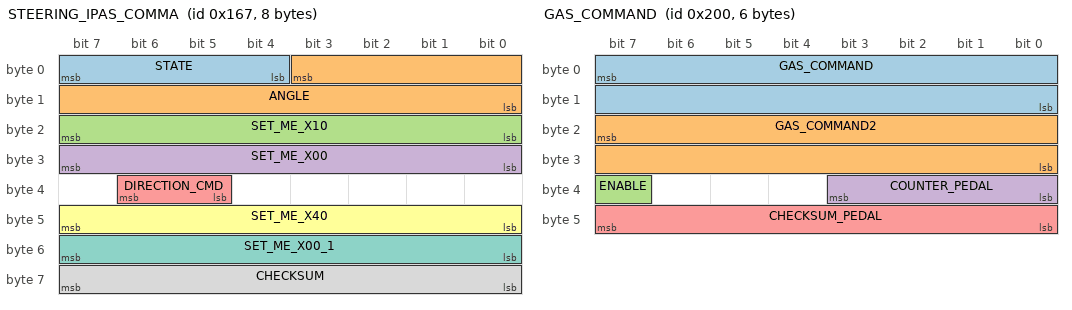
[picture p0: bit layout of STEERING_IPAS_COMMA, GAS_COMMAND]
BO_ 359 STEERING_IPAS_COMMA: 8 IPAS
 SG_ STATE : 7|4@0+ (1,0) [0|15] "" XXX
 SG_ ANGLE : 3|12@0- (1.5,0) [-510|510] "deg" XXX
 SG_ SET_ME_X10 : 23|8@0+ (1,0) [0|255] "" XXX
 SG_ SET_ME_X00 : 31|8@0+ (1,0) [0|255] "" XXX
 SG_ DIRECTION_CMD : 38|2@0+ (1,0) [0|3] "" XXX
 SG_ SET_ME_X40 : 47|8@0+ (1,0) [0|255] "" XXX
 SG_ SET_ME_X00_1 : 55|8@0+ (1,0) [0|255] "" XXX
 SG_ CHECKSUM : 63|8@0+ (1,0) [0|255] "" XXX

CM_ "BO_ STEERING_IPAS_COMMA: Copy of msg 614 so we can do angle control while the Park Assist ECU is connected (Panda spoofs 614 with 359 on connector J70). Note that addresses 0x266 and 0x167 are checksum-invariant";

BO_ 512 GAS_COMMAND: 6 EON
 SG_ GAS_COMMAND : 7|16@0+ (0.159375,-75.555) [0|1] "" INTERCEPTOR
 SG_ GAS_COMMAND2 : 23|16@0+ (0.159375,-151.111) [0|1] "" INTERCEPTOR
 SG_ ENABLE : 39|1@0+ (1,0) [0|1] "" INTERCEPTOR
 SG_ COUNTER_PEDAL : 35|4@0+ (1,0) [0|15] "" INTERCEPTOR
 SG_ CHECKSUM_PEDAL : 47|8@0+ (1,0) [0|255] "" INTERCEPTOR

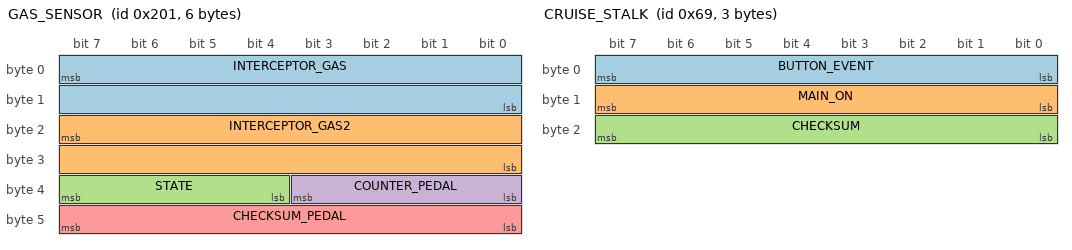
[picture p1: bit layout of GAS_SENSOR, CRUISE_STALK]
BO_ 513 GAS_SENSOR: 6 INTERCEPTOR
 SG_ INTERCEPTOR_GAS : 7|16@0+ (1,0) [0|1] "" EON
 SG_ INTERCEPTOR_GAS2 : 23|16@0+ (1,0) [0|1] "" EON
 SG_ STATE : 39|4@0+ (1,0) [0|15] "" EON
 SG_ COUNTER_PEDAL : 35|4@0+ (1,0) [0|15] "" EON
 SG_ CHECKSUM_PEDAL : 47|8@0+ (1,0) [0|255] "" EON

VAL_ 513 STATE 5 "FAULT_TIMEOUT" 4 "FAULT_STARTUP" 3 "FAULT_SCE" 2 "FAULT_SEND" 1 "FAULT_BAD_CHECKSUM" 0 "NO_FAULT" ;

BO_ 35 SECONDARY_STEER_ANGLE: 8 XXX
 SG_ ZORRO_STEER : 7|24@0- (0.004901594652,0) [-500|500] "" XXX

CM_ "BO_ SECONDARY_STEER_ANGLE: ZSS is a high-precision steering angle sensor that can replace the lower resolution sensor in most TSS1 Toyotas. Learn more: https://github.com/commaai/openpilot/wiki/Toyota-Lexus#zorro-steering-sensor-zss";

BO_ 767 SDSU: 8 XXX
 SG_ FD_BUTTON : 7|1@0+ (1,0) [0|1] "" XXX
 SG_ STATE : 23|4@0+ (1,0) [0|15] "" XXX

CM_ "BO_ SDSU: The sDSU is a modified DSU for use in TSS-P Toyotas. Learn more: https://github.com/RetroPilot/ocelot/tree/main/firmware/smart_dsu";
CM_ SG_ 767 FD_BUTTON "The follow distance button signal as forwarded by the sdsu";

VAL_ 767 STATE 7 "STATE_AEB_CTRL" 6 "FAULT_INVALID" 5 "FAULT_TIMEOUT" 4 "FAULT_STARTUP" 3 "FAULT_SCE" 2 "FAULT_SEND" 1 "FAULT_BAD_CHECKSUM" 0 "NO_FAULT" ;

BO_ 105 CRUISE_STALK: 3 RETROFIT
 SG_ BUTTON_EVENT : 7|8@0+ (1,0) [0|4] "" XXX
 SG_ MAIN_ON : 15|8@0+ (1,0) [0|1] "" XXX
 SG_ CHECKSUM : 23|8@0+ (1,0) [0|255] "" XXX

CM_ "BO_ CRUISE_STALK: Retrofit (TOYOTA_COROLLA_RETROFIT) cruise stalk ECU, 20 Hz. BUTTON_EVENT is set for one frame per press; MAIN_ON is sent every frame. Source: corolla_emulator/cruise_stalk.";
VAL_ 105 BUTTON_EVENT 4 "MAIN_TOGGLE" 3 "CANCEL" 2 "RES" 1 "SET" 0 "NONE" ;

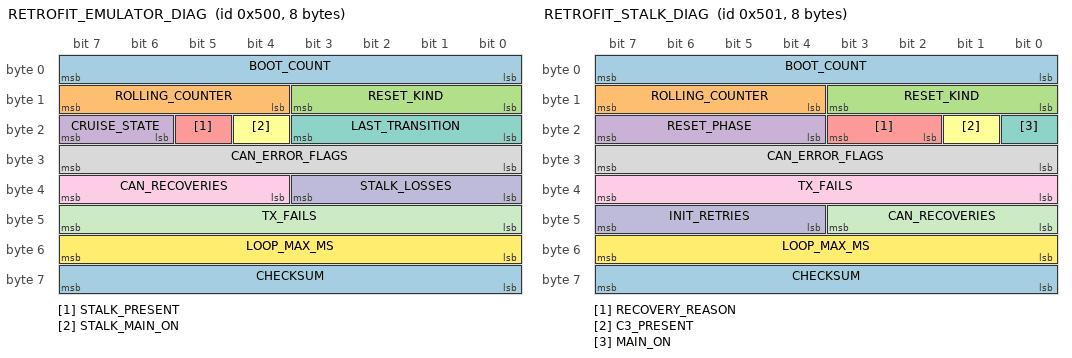
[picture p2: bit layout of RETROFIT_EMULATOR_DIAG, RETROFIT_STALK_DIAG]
BO_ 1280 RETROFIT_EMULATOR_DIAG: 8 RETROFIT
 SG_ BOOT_COUNT : 7|8@0+ (1,0) [0|255] "" XXX
 SG_ ROLLING_COUNTER : 15|4@0+ (1,0) [0|15] "" XXX
 SG_ RESET_KIND : 11|4@0+ (1,0) [0|15] "" XXX
 SG_ CRUISE_STATE : 23|2@0+ (1,0) [0|3] "" XXX
 SG_ STALK_PRESENT : 21|1@0+ (1,0) [0|1] "" XXX
 SG_ STALK_MAIN_ON : 20|1@0+ (1,0) [0|1] "" XXX
 SG_ LAST_TRANSITION : 19|4@0+ (1,0) [0|15] "" XXX
 SG_ CAN_ERROR_FLAGS : 31|8@0+ (1,0) [0|255] "" XXX
 SG_ CAN_RECOVERIES : 39|4@0+ (1,0) [0|15] "" XXX
 SG_ STALK_LOSSES : 35|4@0+ (1,0) [0|15] "" XXX
 SG_ TX_FAILS : 47|8@0+ (1,0) [0|255] "" XXX
 SG_ LOOP_MAX_MS : 55|8@0+ (1,0) [0|255] "ms" XXX
 SG_ CHECKSUM : 63|8@0+ (1,0) [0|255] "" XXX

CM_ "BO_ RETROFIT_EMULATOR_DIAG: Retrofit main emulator ECU status, 2 Hz plus one frame on every cruise transition. Source: corolla_emulator/fakeecu. ROLLING_COUNTER is deliberately not named COUNTER: the parser would treat the jump after an ECU reboot as a CAN error.";
CM_ SG_ 1280 CAN_ERROR_FLAGS "MCP2515 EFLG OR-latched since the previous frame. Bit 6 RX0OVR = a stalk (0x69) frame was dropped; bit 7 RX1OVR = a 0xAA/0x343 frame was dropped; bit 5 TXBO = bus-off.";
VAL_ 1280 RESET_KIND 5 "DELIBERATE" 4 "WATCHDOG" 3 "EXTERNAL" 2 "BROWN_OUT" 1 "POWER_ON" 0 "UNKNOWN" ;
VAL_ 1280 CRUISE_STATE 3 "CANCELLED" 2 "ENGAGED" 1 "MAIN_ON" 0 "OFF" ;
VAL_ 1280 LAST_TRANSITION 12 "RES_INC" 11 "SET_DEC" 10 "FIRST_SYNC" 9 "OP_CANCEL" 8 "STALK_LOST" 7 "MAIN_SYNC_OFF" 6 "MAIN_SYNC_ON" 5 "MAIN_OFF" 4 "MAIN_ON" 3 "CANCEL" 2 "RES" 1 "SET" 0 "BOOT" ;

BO_ 1281 RETROFIT_STALK_DIAG: 8 RETROFIT
 SG_ BOOT_COUNT : 7|8@0+ (1,0) [0|255] "" XXX
 SG_ ROLLING_COUNTER : 15|4@0+ (1,0) [0|15] "" XXX
 SG_ RESET_KIND : 11|4@0+ (1,0) [0|15] "" XXX
 SG_ RESET_PHASE : 23|4@0+ (1,0) [0|15] "" XXX
 SG_ RECOVERY_REASON : 19|2@0+ (1,0) [0|3] "" XXX
 SG_ C3_PRESENT : 17|1@0+ (1,0) [0|1] "" XXX
 SG_ MAIN_ON : 16|1@0+ (1,0) [0|1] "" XXX
 SG_ CAN_ERROR_FLAGS : 31|8@0+ (1,0) [0|255] "" XXX
 SG_ TX_FAILS : 39|8@0+ (1,0) [0|255] "" XXX
 SG_ INIT_RETRIES : 47|4@0+ (1,0) [0|15] "" XXX
 SG_ CAN_RECOVERIES : 43|4@0+ (1,0) [0|15] "" XXX
 SG_ LOOP_MAX_MS : 55|8@0+ (1,0) [0|255] "ms" XXX
 SG_ CHECKSUM : 63|8@0+ (1,0) [0|255] "" XXX

CM_ "BO_ RETROFIT_STALK_DIAG: Retrofit cruise stalk ECU status, 2 Hz plus one frame right after boot and after a CAN recovery. Source: corolla_emulator/cruise_stalk.";
CM_ SG_ 1281 RESET_PHASE "Loop phase the watchdog caught the board in (only meaningful when RESET_KIND is WATCHDOG or DELIBERATE).";
VAL_ 1281 RESET_KIND 5 "DELIBERATE" 4 "WATCHDOG" 3 "EXTERNAL" 2 "BROWN_OUT" 1 "POWER_ON" 0 "UNKNOWN" ;
VAL_ 1281 RESET_PHASE 9 "LOOP" 8 "RECOVERY" 7 "SERIAL" 6 "HEALTH" 5 "CAN_TX" 4 "STALK" 3 "CAN_RX" 2 "CAN_INIT" 1 "SETUP" 0 "NONE" ;
VAL_ 1281 RECOVERY_REASON 3 "BUS_OFF" 2 "MODE_LOST" 1 "TX_STUCK" 0 "NONE" ;

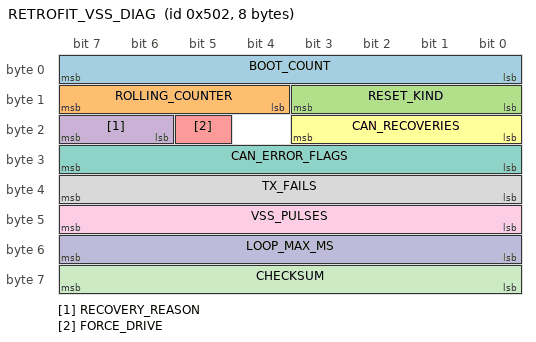
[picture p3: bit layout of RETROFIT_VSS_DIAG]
BO_ 1282 RETROFIT_VSS_DIAG: 8 RETROFIT
 SG_ BOOT_COUNT : 7|8@0+ (1,0) [0|255] "" XXX
 SG_ ROLLING_COUNTER : 15|4@0+ (1,0) [0|15] "" XXX
 SG_ RESET_KIND : 11|4@0+ (1,0) [0|15] "" XXX
 SG_ RECOVERY_REASON : 23|2@0+ (1,0) [0|3] "" XXX
 SG_ FORCE_DRIVE : 21|1@0+ (1,0) [0|1] "" XXX
 SG_ CAN_RECOVERIES : 19|4@0+ (1,0) [0|15] "" XXX
 SG_ CAN_ERROR_FLAGS : 31|8@0+ (1,0) [0|255] "" XXX
 SG_ TX_FAILS : 39|8@0+ (1,0) [0|255] "" XXX
 SG_ VSS_PULSES : 47|8@0+ (1,0) [0|255] "" XXX
 SG_ LOOP_MAX_MS : 55|8@0+ (1,0) [0|255] "ms" XXX
 SG_ CHECKSUM : 63|8@0+ (1,0) [0|255] "" XXX

CM_ "BO_ RETROFIT_VSS_DIAG: Retrofit VSS speed ECU status, 2 Hz. Source: corolla_emulator/vss_speed. CAN_ERROR_FLAGS has the RX overflow bits masked (the device never reads RX).";
VAL_ 1282 RESET_KIND 5 "DELIBERATE" 4 "WATCHDOG" 3 "EXTERNAL" 2 "BROWN_OUT" 1 "POWER_ON" 0 "UNKNOWN" ;
VAL_ 1282 RECOVERY_REASON 3 "BUS_OFF" 2 "MODE_LOST" 1 "TX_STUCK" 0 "NONE" ;

BO_ 1283 RETROFIT_EMULATOR_VERSION: 8 RETROFIT
 SG_ PAGE M : 7|8@0+ (1,0) [0|255] "" XXX
 SG_ VERSION_CHAR_1 m0 : 15|8@0+ (1,0) [0|255] "" XXX
 SG_ VERSION_CHAR_2 m0 : 23|8@0+ (1,0) [0|255] "" XXX
 SG_ VERSION_CHAR_3 m0 : 31|8@0+ (1,0) [0|255] "" XXX
 SG_ VERSION_CHAR_4 m0 : 39|8@0+ (1,0) [0|255] "" XXX
 SG_ VERSION_CHAR_5 m0 : 47|8@0+ (1,0) [0|255] "" XXX
 SG_ VERSION_CHAR_6 m0 : 55|8@0+ (1,0) [0|255] "" XXX
 SG_ VERSION_CHAR_7 m0 : 63|8@0+ (1,0) [0|255] "" XXX
 SG_ BUILD_YEAR m1 : 15|8@0+ (1,2000) [2000|2255] "" XXX
 SG_ BUILD_MONTH m1 : 23|8@0+ (1,0) [0|255] "" XXX
 SG_ BUILD_DAY m1 : 31|8@0+ (1,0) [0|255] "" XXX
 SG_ BUILD_HOUR m1 : 39|8@0+ (1,0) [0|255] "" XXX
 SG_ BUILD_MINUTE m1 : 47|8@0+ (1,0) [0|255] "" XXX
 SG_ BUILD_SECOND m1 : 55|8@0+ (1,0) [0|255] "" XXX

CM_ "BO_ RETROFIT_EMULATOR_VERSION: Firmware version of the retrofit ECU (corolla_emulator/fakeecu), alternating pages at 2 Hz. Page 0: FW_VERSION tag as 7 ASCII bytes (MMDDYY + a-z/0-9). Page 1: compile timestamp. For our own records only, never used for fingerprinting.";
VAL_ 1283 PAGE 1 "BUILD_TIME" 0 "VERSION" ;

BO_ 1284 RETROFIT_STALK_VERSION: 8 RETROFIT
 SG_ PAGE M : 7|8@0+ (1,0) [0|255] "" XXX
 SG_ VERSION_CHAR_1 m0 : 15|8@0+ (1,0) [0|255] "" XXX
 SG_ VERSION_CHAR_2 m0 : 23|8@0+ (1,0) [0|255] "" XXX
 SG_ VERSION_CHAR_3 m0 : 31|8@0+ (1,0) [0|255] "" XXX
 SG_ VERSION_CHAR_4 m0 : 39|8@0+ (1,0) [0|255] "" XXX
 SG_ VERSION_CHAR_5 m0 : 47|8@0+ (1,0) [0|255] "" XXX
 SG_ VERSION_CHAR_6 m0 : 55|8@0+ (1,0) [0|255] "" XXX
 SG_ VERSION_CHAR_7 m0 : 63|8@0+ (1,0) [0|255] "" XXX
 SG_ BUILD_YEAR m1 : 15|8@0+ (1,2000) [2000|2255] "" XXX
 SG_ BUILD_MONTH m1 : 23|8@0+ (1,0) [0|255] "" XXX
 SG_ BUILD_DAY m1 : 31|8@0+ (1,0) [0|255] "" XXX
 SG_ BUILD_HOUR m1 : 39|8@0+ (1,0) [0|255] "" XXX
 SG_ BUILD_MINUTE m1 : 47|8@0+ (1,0) [0|255] "" XXX
 SG_ BUILD_SECOND m1 : 55|8@0+ (1,0) [0|255] "" XXX

CM_ "BO_ RETROFIT_STALK_VERSION: Firmware version of the retrofit ECU (corolla_emulator/cruise_stalk), alternating pages at 2 Hz. Page 0: FW_VERSION tag as 7 ASCII bytes (MMDDYY + a-z/0-9). Page 1: compile timestamp. For our own records only, never used for fingerprinting.";
VAL_ 1284 PAGE 1 "BUILD_TIME" 0 "VERSION" ;

BO_ 1285 RETROFIT_VSS_VERSION: 8 RETROFIT
 SG_ PAGE M : 7|8@0+ (1,0) [0|255] "" XXX
 SG_ VERSION_CHAR_1 m0 : 15|8@0+ (1,0) [0|255] "" XXX
 SG_ VERSION_CHAR_2 m0 : 23|8@0+ (1,0) [0|255] "" XXX
 SG_ VERSION_CHAR_3 m0 : 31|8@0+ (1,0) [0|255] "" XXX
 SG_ VERSION_CHAR_4 m0 : 39|8@0+ (1,0) [0|255] "" XXX
 SG_ VERSION_CHAR_5 m0 : 47|8@0+ (1,0) [0|255] "" XXX
 SG_ VERSION_CHAR_6 m0 : 55|8@0+ (1,0) [0|255] "" XXX
 SG_ VERSION_CHAR_7 m0 : 63|8@0+ (1,0) [0|255] "" XXX
 SG_ BUILD_YEAR m1 : 15|8@0+ (1,2000) [2000|2255] "" XXX
 SG_ BUILD_MONTH m1 : 23|8@0+ (1,0) [0|255] "" XXX
 SG_ BUILD_DAY m1 : 31|8@0+ (1,0) [0|255] "" XXX
 SG_ BUILD_HOUR m1 : 39|8@0+ (1,0) [0|255] "" XXX
 SG_ BUILD_MINUTE m1 : 47|8@0+ (1,0) [0|255] "" XXX
 SG_ BUILD_SECOND m1 : 55|8@0+ (1,0) [0|255] "" XXX

CM_ "BO_ RETROFIT_VSS_VERSION: Firmware version of the retrofit ECU (corolla_emulator/vss_speed), alternating pages at 2 Hz. Page 0: FW_VERSION tag as 7 ASCII bytes (MMDDYY + a-z/0-9). Page 1: compile timestamp. For our own records only, never used for fingerprinting.";
VAL_ 1285 PAGE 1 "BUILD_TIME" 0 "VERSION" ;
